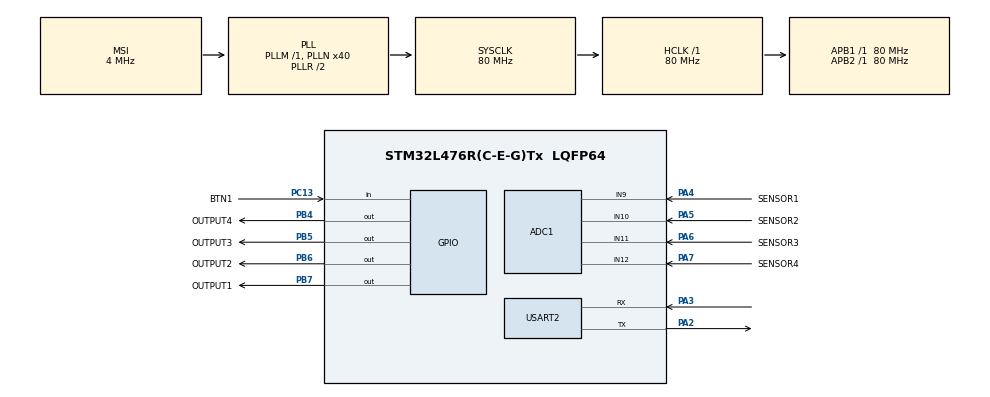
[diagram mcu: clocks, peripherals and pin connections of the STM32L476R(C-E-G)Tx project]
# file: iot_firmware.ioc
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ADC1.Channel-0\#ChannelRegularConversion=ADC_CHANNEL_9
ADC1.Channel-1\#ChannelRegularConversion=ADC_CHANNEL_9
ADC1.Channel-2\#ChannelRegularConversion=ADC_CHANNEL_9
ADC1.Channel-3\#ChannelRegularConversion=ADC_CHANNEL_9
ADC1.ClockPrescaler=ADC_CLOCK_ASYNC_DIV8
ADC1.ContinuousConvMode=ENABLE
ADC1.DMAContinuousRequests=ENABLE
ADC1.NbrOfConversion=4
ADC1.NbrOfConversionFlag=1
ADC1.OffsetNumber-0\#ChannelRegularConversion=ADC_OFFSET_NONE
ADC1.OffsetNumber-1\#ChannelRegularConversion=ADC_OFFSET_NONE
ADC1.OffsetNumber-2\#ChannelRegularConversion=ADC_OFFSET_NONE
ADC1.OffsetNumber-3\#ChannelRegularConversion=ADC_OFFSET_NONE
ADC1.Rank-0\#ChannelRegularConversion=1
ADC1.Rank-1\#ChannelRegularConversion=2
ADC1.Rank-2\#ChannelRegularConversion=3
ADC1.Rank-3\#ChannelRegularConversion=4
ADC1.SamplingTime-0\#ChannelRegularConversion=ADC_SAMPLETIME_640CYCLES_5
ADC1.SamplingTime-1\#ChannelRegularConversion=ADC_SAMPLETIME_640CYCLES_5
ADC1.SamplingTime-2\#ChannelRegularConversion=ADC_SAMPLETIME_640CYCLES_5
ADC1.SamplingTime-3\#ChannelRegularConversion=ADC_SAMPLETIME_640CYCLES_5
ADC1.master=1
Dma.ADC1.0.Direction=DMA_PERIPH_TO_MEMORY
Dma.ADC1.0.Instance=DMA1_Channel1
Dma.ADC1.0.MemDataAlignment=DMA_MDATAALIGN_WORD
Dma.ADC1.0.MemInc=DMA_MINC_ENABLE
Dma.ADC1.0.Mode=DMA_CIRCULAR
Dma.ADC1.0.PeriphDataAlignment=DMA_PDATAALIGN_WORD
Dma.ADC1.0.PeriphInc=DMA_PINC_DISABLE
Dma.ADC1.0.Priority=DMA_PRIORITY_LOW
Dma.Request0=ADC1
FREERTOS.Mutexes01=tx_mutex,Dynamic,NULL
FREERTOS.Tasks01=defaultTask,0,128,StartDefaultTask,Default,NULL,Dynamic,NULL,NULL;Tread1,-3,128,Tread1Func,Default,NULL,Dynamic,NULL,NULL;Tread2,-3,128,Tread2Func,Default,NULL,Dynamic,NULL,NULL
Mcu.Family=STM32L4
Mcu.Name=STM32L476R(C-E-G)Tx
Mcu.Package=LQFP64
NVIC.DMA1_Channel1_IRQn=true\:5\:0\:false\:false\:true\:true\:false\:true\:true
NVIC.PriorityGroup=NVIC_PRIORITYGROUP_4
NVIC.TIM3_IRQn=true\:15\:0\:false\:false\:true\:false\:false\:true\:true
NVIC.TimeBase=TIM3_IRQn
NVIC.TimeBaseIP=TIM3
PA13\ (JTMS-SWDIO).Mode=Serial_Wire
PA13\ (JTMS-SWDIO).Signal=SYS_JTMS-SWDIO
PA14\ (JTCK-SWCLK).Mode=Serial_Wire
PA14\ (JTCK-SWCLK).Signal=SYS_JTCK-SWCLK
PA2.Mode=Asynchronous
PA2.Signal=USART2_TX
PA3.Mode=Asynchronous
PA3.Signal=USART2_RX
PA4.GPIO_Label=SENSOR1
PA4.Signal=ADCx_IN9
PA5.GPIO_Label=SENSOR2
PA5.Signal=ADCx_IN10
PA6.GPIO_Label=SENSOR3
PA6.Signal=ADCx_IN11
PA7.GPIO_Label=SENSOR4
PA7.Signal=ADCx_IN12
PB4\ (NJTRST).GPIO_Label=OUTPUT4
PB4\ (NJTRST).Signal=GPIO_Output
PB5.GPIO_Label=OUTPUT3
PB5.Signal=GPIO_Output
PB6.GPIO_Label=OUTPUT2
PB6.Signal=GPIO_Output
PB7.GPIO_Label=OUTPUT1
PB7.Signal=GPIO_Output
PC13.GPIO_Label=BTN1
PC13.Signal=GPIO_Input
PC14-OSC32_IN\ (PC14).Mode=LSE-External-Oscillator
PC14-OSC32_IN\ (PC14).Signal=RCC_OSC32_IN
PC15-OSC32_OUT\ (PC15).Mode=LSE-External-Oscillator
PC15-OSC32_OUT\ (PC15).Signal=RCC_OSC32_OUT
PH0-OSC_IN\ (PH0).Mode=HSE-External-Clock-Source
PH0-OSC_IN\ (PH0).Signal=RCC_OSC_IN
ProjectManager.HeapSize=0x2000
ProjectManager.StackSize=0x4000
ProjectManager.TargetToolchain=STM32CubeIDE
RCC.ADCFreq_Value=32000000
RCC.AHBFreq_Value=80000000
RCC.APB1Freq_Value=80000000
RCC.APB1TimFreq_Value=80000000
RCC.APB2Freq_Value=80000000
RCC.APB2TimFreq_Value=80000000
RCC.CortexFreq_Value=80000000
RCC.HCLKFreq_Value=80000000
RCC.HSE_VALUE=8000000
RCC.HSI_VALUE=16000000
RCC.MSI_VALUE=4000000
RCC.PLLN=40
RCC.PLLSAI1N=16
RCC.SYSCLKFreq_VALUE=80000000
RCC.SYSCLKSource=RCC_SYSCLKSOURCE_PLLCLK
RCC.USBFreq_Value=32000000
RCC.VCOOutputFreq_Value=160000000
SH.ADCx_IN10.0=ADC1_IN10,IN10-Single-Ended
SH.ADCx_IN11.0=ADC1_IN11,IN11-Single-Ended
SH.ADCx_IN12.0=ADC1_IN12,IN12-Single-Ended
SH.ADCx_IN9.0=ADC1_IN9,IN9-Single-Ended
USART2.VirtualMode-Asynchronous=VM_ASYNC
VP_FREERTOS_VS_CMSIS_V1.Mode=CMSIS_V1
VP_SYS_VS_tim3.Mode=TIM3
board=custom

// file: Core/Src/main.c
#include "main.h"
#include "cmsis_os.h"
#include "adc.h"
#include "dma.h"
#include "usart.h"
#include "gpio.h"

void SystemClock_Config(void);
void MX_FREERTOS_Init(void);

int main(void)
{

  /* MCU Configuration--------------------------------------------------------*/

  /* Reset of all peripherals, Initializes the Flash interface and the Systick. */
  HAL_Init();

  /* Configure the system clock */
  SystemClock_Config();

  /* Initialize all configured peripherals */
  MX_GPIO_Init();
  MX_DMA_Init();
  MX_ADC1_Init();
  MX_USART2_UART_Init();

  /* Call init function for freertos objects (in freertos.c) */
  MX_FREERTOS_Init();

  /* Start scheduler */
  osKernelStart();

  /* We should never get here as control is now taken by the scheduler */
  /* Infinite loop */
  while (1)
  {

  }
}

void SystemClock_Config(void)
{
  RCC_OscInitTypeDef RCC_OscInitStruct = {0};
  RCC_ClkInitTypeDef RCC_ClkInitStruct = {0};

  /** Configure the main internal regulator output voltage
  */
  if (HAL_PWREx_ControlVoltageScaling(PWR_REGULATOR_VOLTAGE_SCALE1) != HAL_OK)
  {
    Error_Handler();
  }

  /** Configure LSE Drive Capability
  */
  HAL_PWR_EnableBkUpAccess();
  __HAL_RCC_LSEDRIVE_CONFIG(RCC_LSEDRIVE_LOW);

  /** Initializes the RCC Oscillators according to the specified parameters
  * in the RCC_OscInitTypeDef structure.
  */
  RCC_OscInitStruct.OscillatorType = RCC_OSCILLATORTYPE_LSE|RCC_OSCILLATORTYPE_MSI;
  RCC_OscInitStruct.LSEState = RCC_LSE_ON;
  RCC_OscInitStruct.MSIState = RCC_MSI_ON;
  RCC_OscInitStruct.MSICalibrationValue = 0;
  RCC_OscInitStruct.MSIClockRange = RCC_MSIRANGE_6;
  RCC_OscInitStruct.PLL.PLLState = RCC_PLL_ON;
  RCC_OscInitStruct.PLL.PLLSource = RCC_PLLSOURCE_MSI;
  RCC_OscInitStruct.PLL.PLLM = 1;
  RCC_OscInitStruct.PLL.PLLN = 40;
  RCC_OscInitStruct.PLL.PLLP = RCC_PLLP_DIV7;
  RCC_OscInitStruct.PLL.PLLQ = RCC_PLLQ_DIV2;
  RCC_OscInitStruct.PLL.PLLR = RCC_PLLR_DIV2;
  if (HAL_RCC_OscConfig(&RCC_OscInitStruct) != HAL_OK)
  {
    Error_Handler();
  }

  /** Initializes the CPU, AHB and APB buses clocks
  */
  RCC_ClkInitStruct.ClockType = RCC_CLOCKTYPE_HCLK|RCC_CLOCKTYPE_SYSCLK
                              |RCC_CLOCKTYPE_PCLK1|RCC_CLOCKTYPE_PCLK2;
  RCC_ClkInitStruct.SYSCLKSource = RCC_SYSCLKSOURCE_PLLCLK;
  RCC_ClkInitStruct.AHBCLKDivider = RCC_SYSCLK_DIV1;
  RCC_ClkInitStruct.APB1CLKDivider = RCC_HCLK_DIV1;
  RCC_ClkInitStruct.APB2CLKDivider = RCC_HCLK_DIV1;

  if (HAL_RCC_ClockConfig(&RCC_ClkInitStruct, FLASH_LATENCY_4) != HAL_OK)
  {
    Error_Handler();
  }

  /** Enable MSI Auto calibration
  */
  HAL_RCCEx_EnableMSIPLLMode();
}

void HAL_TIM_PeriodElapsedCallback(TIM_HandleTypeDef *htim)
{
  if (htim->Instance == TIM3) {
    HAL_IncTick();
  }
}

void Error_Handler(void)
{
  __disable_irq();
  while (1)
  {
  }
}

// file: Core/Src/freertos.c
/* USER CODE BEGIN Header */
/**
  ******************************************************************************
  * File Name          : freertos.c
  * Description        : Code for freertos applications
  ******************************************************************************
  * @attention
  *
  * Copyright (c) 2025 STMicroelectronics.
  * All rights reserved.
  *
  * This software is licensed under terms that can be found in the LICENSE file
  * in the root directory of this software component.
  * If no LICENSE file comes with this software, it is provided AS-IS.
  *
  ******************************************************************************
  */
/* USER CODE END Header */

#include "FreeRTOS.h"
#include "task.h"
#include "main.h"
#include "cmsis_os.h"

#include "usart.h"
#include "adc.h"

osThreadId defaultTaskHandle;
osThreadId Tread1Handle;
osThreadId Tread2Handle;
osMutexId tx_mutexHandle;

typedef uint32_t ThreadProfiler_T;

ThreadProfiler_T DefaultThread_Profiler, Thread1_Profiler, Thread2_Profiler;

UART_HandleTypeDef huart2;

ADC_HandleTypeDef hadc1;
uint32_t sensorValues[4];

uint8_t buttonStatus;

void StartDefaultTask(void const * argument);
void Tread1Func(void const * argument);
void Tread2Func(void const * argument);

void MX_FREERTOS_Init(void); /* (MISRA C 2004 rule 8.1) */

/* GetIdleTaskMemory prototype (linked to static allocation support) */
void vApplicationGetIdleTaskMemory( StaticTask_t **ppxIdleTaskTCBBuffer, StackType_t **ppxIdleTaskStackBuffer, uint32_t *pulIdleTaskStackSize );

/* USER CODE BEGIN GET_IDLE_TASK_MEMORY */
static StaticTask_t xIdleTaskTCBBuffer;
static StackType_t xIdleStack[configMINIMAL_STACK_SIZE];

void vApplicationGetIdleTaskMemory( StaticTask_t **ppxIdleTaskTCBBuffer, StackType_t **ppxIdleTaskStackBuffer, uint32_t *pulIdleTaskStackSize )
{
  *ppxIdleTaskTCBBuffer = &xIdleTaskTCBBuffer;
  *ppxIdleTaskStackBuffer = &xIdleStack[0];
  *pulIdleTaskStackSize = configMINIMAL_STACK_SIZE;
  /* place for user code */
}
/* USER CODE END GET_IDLE_TASK_MEMORY */

void MX_FREERTOS_Init(void) {
  /* USER CODE BEGIN Init */
	HAL_ADC_Start_DMA(&hadc1, sensorValues, 4);
  /* USER CODE END Init */
  /* Create the mutex(es) */
  /* definition and creation of tx_mutex */
  osMutexDef(tx_mutex);
  tx_mutexHandle = osMutexCreate(osMutex(tx_mutex));

  /* Create the thread(s) */
  /* definition and creation of defaultTask */
  osThreadDef(defaultTask, StartDefaultTask, osPriorityNormal, 0, 128);
  defaultTaskHandle = osThreadCreate(osThread(defaultTask), NULL);

  /* definition and creation of Tread1 */
  osThreadDef(Tread1, Tread1Func, osPriorityIdle, 0, 128);
  Tread1Handle = osThreadCreate(osThread(Tread1), NULL);

  /* definition and creation of Tread2 */
  osThreadDef(Tread2, Tread2Func, osPriorityIdle, 0, 128);
  Tread2Handle = osThreadCreate(osThread(Tread2), NULL);

}

void StartDefaultTask(void const * argument)
{
  /* USER CODE BEGIN StartDefaultTask */
  /* Infinite loop */
  for(;;)
  {
	  DefaultThread_Profiler++;
    osDelay(1);
  }
  /* USER CODE END StartDefaultTask */
}

void Tread1Func(void const * argument)
{
  for(;;)
  {
	  Thread1_Profiler++;
	  xSemaphoreTake(tx_mutexHandle, portMAX_DELAY);

	  // Test 1
	  uart_outchar('A');
	  uart_outdec(sensorValues[0]); // Temperature sensor at PA4 (ADC1_IN4)
	  uart_outcrfl();

	  uart_outchar('B');
	  uart_outdec(sensorValues[1]); // Pressure sensor at PA5 (ADC1_IN5)
	  uart_outcrfl();

	  uart_outchar('C');
	  uart_outdec(sensorValues[2]); // Battery 1 at PA6 (ADC1_IN6)
	  uart_outcrfl();

	  uart_outchar('D');
	  uart_outdec(sensorValues[3]); // Battery 2 at PA7 (ADC1_IN7)
	  uart_outcrfl();

	  xSemaphoreGive(tx_mutexHandle);

	  osDelay(1);
  }
}

uint8_t recv[2]; // Receiving data

void Tread2Func(void const * argument)
{

  for(;;)
  {
	  Thread2_Profiler++;

	  xSemaphoreTake(tx_mutexHandle, portMAX_DELAY);

	  HAL_UART_Receive(&huart2, recv, 4, 1000);

	  if (recv[0] == 65)
	  {
		  if (recv[1] == 49)
		  {
			  HAL_GPIO_WritePin(OUTPUT1_GPIO_Port, OUTPUT1_Pin, GPIO_PIN_SET);
		  }
		  else
		  {
			  HAL_GPIO_WritePin(OUTPUT1_GPIO_Port, OUTPUT1_Pin, GPIO_PIN_RESET);
		  }

	  }

	  if (recv[0] == 66)
	  {
		  if (recv[1] == 49)
		  {
			  HAL_GPIO_WritePin(OUTPUT2_GPIO_Port, OUTPUT2_Pin, GPIO_PIN_SET);
		  }
		  else
		  {
			  HAL_GPIO_WritePin(OUTPUT2_GPIO_Port, OUTPUT2_Pin, GPIO_PIN_RESET);
		  }

	  }

	  xSemaphoreGive(tx_mutexHandle);

	  buttonStatus = HAL_GPIO_ReadPin(BTN1_GPIO_Port, BTN1_Pin);

	  osDelay(1);

  }
}
